# LPC55S66_cm33_core1 register map
Vendor: nxp.com; File version: 1.0
CPU: CM33 r2p0, little endian, no MPU, no FPU, VTOR, 3 interrupt priority bits
Registers are 32-bit, read-write, reset 0x0 unless marked. A register's access mark holds for its fields unless they carry their own. Offsets are from the block's base; [hi:lo] are bit positions; lines under a group give offsets from that group; {n}, {i} and the like mark numbered series; 'fields as' and 'values as' point back to an identical list.

## SCT0 — SCTimer/PWM (SCT)
Base 0x40085000
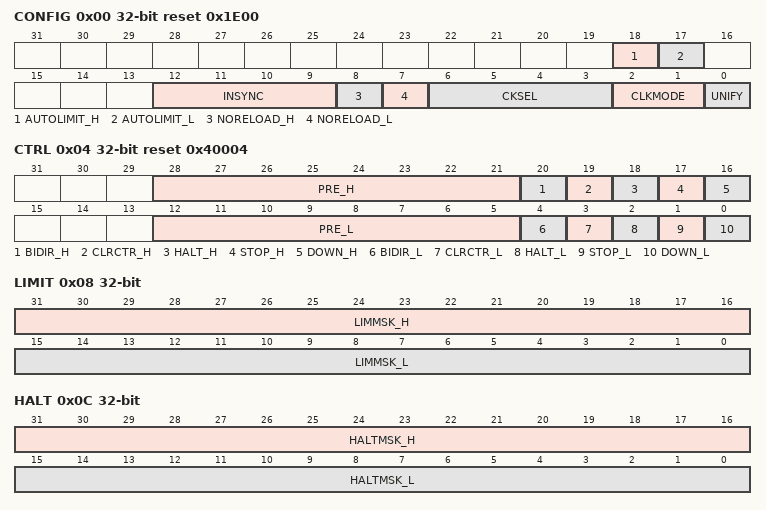
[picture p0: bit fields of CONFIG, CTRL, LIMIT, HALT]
0x00 CONFIG reset 0x1E00 — SCT configuration register
  [18] AUTOLIMIT_H — A one in this bit will cause a match on match register 0 to be treated as a de-facto LIMIT condition without the need to define an associated event. As with any LIMIT event, this automatic limit causes the counter to be cleared to zero in unidirectional mode or to change the direction of count in bi-directional mode. Software can write to set or clear this bit at any time. This bit is not used when the UNIFY bit is set.
  [17] AUTOLIMIT_L — A one in this bit causes a match on match register 0 to be treated as a de-facto LIMIT condition without the need to define an associated event. As with any LIMIT event, this automatic limit causes the counter to be cleared to zero in unidirectional mode or to change the direction of count in bi-directional mode. Software can write to set or clear this bit at any time. This bit applies to both the higher and lower registers when the UNIFY bit is set.
  [12:9] INSYNC — Synchronization for input N (bit 9 = input 0, bit 10 = input 1,, bit 12 = input 3); all other bits are reserved. A 1 in one of these bits subjects the corresponding input to synchronization to the SCT clock, before it is used to create an event. If an input is known to already be synchronous to the SCT clock, this bit may be set to 0 for faster input response. (Note: The SCT clock is the system clock for CKMODEs 0-2. It is the selected, asynchronous SCT input clock for CKMODE3). Note that the INSYNC field only affects inputs used for event generation. It does not apply to the clock input specified in the CKSEL field.
  [8] NORELOAD_H — A 1 in this bit prevents the higher match registers from being reloaded from their respective reload registers. Setting this bit eliminates the need to write to the reload registers MATCHREL if the match values are fixed. Software can write to set or clear this bit at any time. This bit is not used when the UNIFY bit is set.
  [7] NORELOAD_L — A 1 in this bit prevents the lower match registers from being reloaded from their respective reload registers. Setting this bit eliminates the need to write to the reload registers MATCHREL if the match values are fixed. Software can write to set or clear this bit at any time. This bit applies to both the higher and lower registers when the UNIFY bit is set.
  [6:3] CKSEL — SCT clock select. The specific functionality of the designated input/edge is dependent on the CLKMODE bit selection in this register.
    0=INPUT_0_RISING_EDGES (Rising edges on input 0.); 1=INPUT_0_FALLING_EDGE (Falling edges on input 0.); 2=INPUT_1_RISING_EDGES (Rising edges on input 1.); 3=INPUT_1_FALLING_EDGE (Falling edges on input 1.); 4=INPUT_2_RISING_EDGES (Rising edges on input 2.); 5=INPUT_2_FALLING_EDGE (Falling edges on input 2.); 6=INPUT_3_RISING_EDGES (Rising edges on input 3.); 7=INPUT_3_FALLING_EDGE (Falling edges on input 3.); 8=INPUT_4_RISING_EDGES (Rising edges on input 4.); 9=INPUT_4_FALLING_EDGE (Falling edges on input 4.); 10=INPUT_5_RISING_EDGES (Rising edges on input 5.); 11=INPUT_5_FALLING_EDGE (Falling edges on input 5.); 12=INPUT_6_RISING_EDGES (Rising edges on input 6.); 13=INPUT_6_FALLING_EDGE (Falling edges on input 6.); 14=INPUT_7_RISING_EDGES (Rising edges on input 7.); 15=INPUT_7_FALLING_EDGE (Falling edges on input 7.)
  [2:1] CLKMODE — SCT clock mode
    0=SYSTEM_CLOCK_MODE (System Clock Mode. The system clock clocks the entire SCT module including the counter(s) and counter prescalers.); 1=SAMPLED_SYSTEM_CLOCK_MODE (Sampled System Clock Mode. The system clock clocks the SCT module, but the counter and prescalers are only enabled to count when the designated edge is detected on the input selected by the CKSEL field. The minimum pulse width on the selected clock-gate input is 1 bus clock period. This mode is the high-performance, sampled-clock mode.); 2=SCT_INPUT_CLOCK_MODE (SCT Input Clock Mode. The input/edge selected by the CKSEL field clocks the SCT module, including the counters and prescalers, after first being synchronized to the system clock. The minimum pulse width on the clock input is 1 bus clock period. This mode is the low-power, sampled-clock mode.); 3=ASYNCHRONOUS_MODE (Asynchronous Mode. The entire SCT module is clocked directly by the input/edge selected by the CKSEL field. In this mode, the SCT outputs are switched synchronously to the SCT input clock - not the system clock. The input clock rate must be at least half the system clock rate and can be the same or faster than the system clock.)
  [0] UNIFY — SCT operation
    0=DUAL_COUNTER (The SCT operates as two 16-bit counters named COUNTER_L and COUNTER_H.); 1=UNIFIED_COUNTER (The SCT operates as a unified 32-bit counter.)
0x04 CTRL reset 0x40004 — SCT control register
  [28:21] PRE_H — Specifies the factor by which the SCT clock is prescaled to produce the H counter clock. The counter clock is clocked at the rate of the SCT clock divided by PRELH+1. Clear the counter (by writing a 1 to the CLRCTR bit) whenever changing the PRE value.
  [20] BIDIR_H — Direction select
    0=UP (The H counter counts up to its limit condition, then is cleared to zero.); 1=UP_DOWN (The H counter counts up to its limit, then counts down to a limit condition or to 0.)
  [19] CLRCTR_H — Writing a 1 to this bit clears the H counter. This bit always reads as 0.
  [18] HALT_H — When this bit is 1, the H counter does not run and no events can occur. A reset sets this bit. When the HALT_H bit is one, the STOP_H bit is cleared. It is possible to remove the halt condition while keeping the SCT in the stop condition (not running) with a single write to this register to simultaneously clear the HALT bit and set the STOP bit. Once set, this bit can only be cleared by software to restore counter operation. This bit is set on reset.
  [17] STOP_H — When this bit is 1 and HALT is 0, the H counter does not, run but I/O events related to the counter can occur. If such an event matches the mask in the Start register, this bit is cleared and counting resumes.
  [16] DOWN_H — This bit is 1 when the H counter is counting down. Hardware sets this bit when the counter is counting, a counter limit condition occurs, and BIDIR is 1. Hardware clears this bit when the counter is counting down and a limit condition occurs or when the counter reaches 0.
  [12:5] PRE_L — Specifies the factor by which the SCT clock is prescaled to produce the L or unified counter clock. The counter clock is clocked at the rate of the SCT clock divided by PRE_L+1. Clear the counter (by writing a 1 to the CLRCTR bit) whenever changing the PRE value.
  [4] BIDIR_L — L or unified counter direction select
    0=UP (Up. The counter counts up to a limit condition, then is cleared to zero.); 1=UP_DOWN (Up-down. The counter counts up to a limit, then counts down to a limit condition or to 0.)
  [3] CLRCTR_L — Writing a 1 to this bit clears the L or unified counter. This bit always reads as 0.
  [2] HALT_L — When this bit is 1, the L or unified counter does not run and no events can occur. A reset sets this bit. When the HALT_L bit is one, the STOP_L bit is cleared. It is possible to remove the halt condition while keeping the SCT in the stop condition (not running) with a single write to this register to simultaneously clear the HALT bit and set the STOP bit. Once set, only software can clear this bit to restore counter operation. This bit is set on reset.
  [1] STOP_L — When this bit is 1 and HALT is 0, the L or unified counter does not run, but I/O events related to the counter can occur. If a designated start event occurs, this bit is cleared and counting resumes.
  [0] DOWN_L — This bit is 1 when the L or unified counter is counting down. Hardware sets this bit when the counter is counting up, counter limit occurs, and BIDIR = 1.Hardware clears this bit when the counter is counting down and a limit condition occurs or when the counter reaches 0.
0x08 LIMIT — SCT limit event select register
  [31:16] LIMMSK_H — If bit n is one, event n is used as a counter limit for the H counter (event 0 = bit 16, event 1 = bit 17, etc.). The number of bits = number of events in this SCT.
  [15:0] LIMMSK_L — If bit n is one, event n is used as a counter limit for the L or unified counter (event 0 = bit 0, event 1 = bit 1, etc.). The number of bits = number of events in this SCT.
0x0C HALT — SCT halt event select register
  [31:16] HALTMSK_H — If bit n is one, event n sets the HALT_H bit in the CTRL register (event 0 = bit 16, event 1 = bit 17, etc.). The number of bits = number of events in this SCT.
  [15:0] HALTMSK_L — If bit n is one, event n sets the HALT_L bit in the CTRL register (event 0 = bit 0, event 1 = bit 1, etc.). The number of bits = number of events in this SCT.
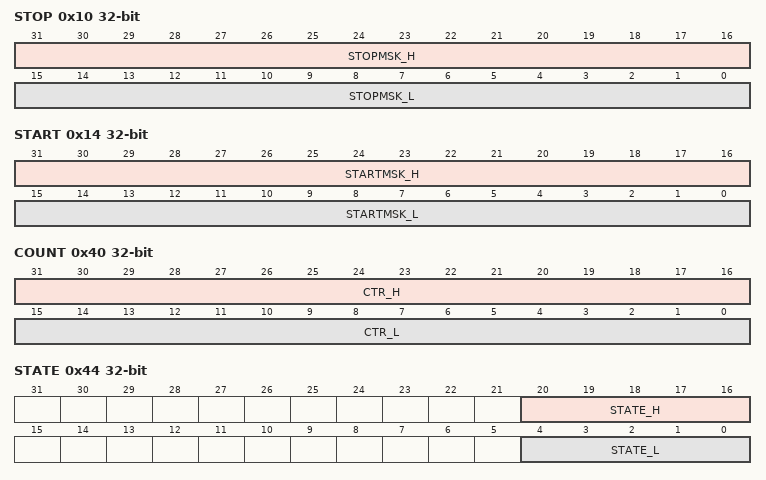
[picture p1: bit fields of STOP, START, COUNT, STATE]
0x10 STOP — SCT stop event select register
  [31:16] STOPMSK_H — If bit n is one, event n sets the STOP_H bit in the CTRL register (event 0 = bit 16, event 1 = bit 17, etc.). The number of bits = number of events in this SCT.
  [15:0] STOPMSK_L — If bit n is one, event n sets the STOP_L bit in the CTRL register (event 0 = bit 0, event 1 = bit 1, etc.). The number of bits = number of events in this SCT.
0x14 START — SCT start event select register
  [31:16] STARTMSK_H — If bit n is one, event n clears the STOP_H bit in the CTRL register (event 0 = bit 16, event 1 = bit 17, etc.). The number of bits = number of events in this SCT.
  [15:0] STARTMSK_L — If bit n is one, event n clears the STOP_L bit in the CTRL register (event 0 = bit 0, event 1 = bit 1, etc.). The number of bits = number of events in this SCT.
0x40 COUNT — SCT counter register
  [31:16] CTR_H — When UNIFY = 0, read or write the 16-bit H counter value. When UNIFY = 1, read or write the upper 16 bits of the 32-bit unified counter.
  [15:0] CTR_L — When UNIFY = 0, read or write the 16-bit L counter value. When UNIFY = 1, read or write the lower 16 bits of the 32-bit unified counter.
0x44 STATE — SCT state register
  [20:16] STATE_H — State variable.
  [4:0] STATE_L — State variable.
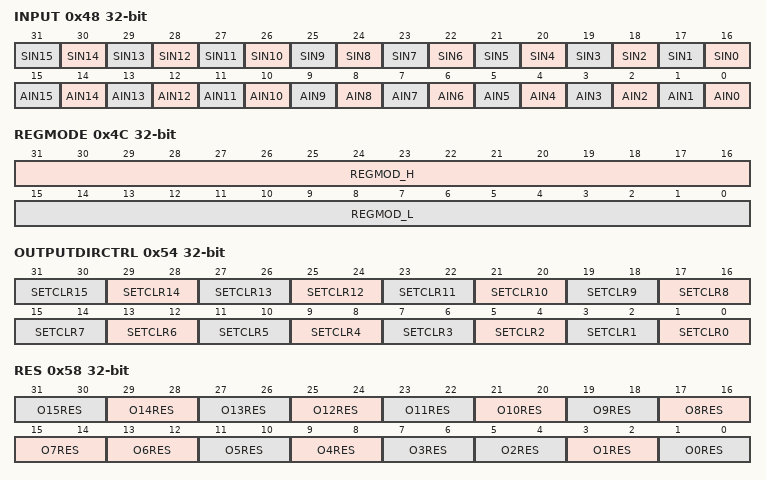
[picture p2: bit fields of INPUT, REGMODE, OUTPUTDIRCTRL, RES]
0x48 INPUT ro — SCT input register
  [n+16] SIN{n} (n=0..15) — Input {n} state. Input {n} state following the synchronization specified by INSYNC.
  [n] AIN{n} (n=0..15) — Input {n} state. Input {n} state on the last SCT clock edge.
0x4C REGMODE — SCT match/capture mode register
  [31:16] REGMOD_H — Each bit controls one match/capture register (register 0 = bit 16, register 1 = bit 17, etc.). The number of bits = number of match/captures in this SCT. 0 = register operates as match registers. 1 = register operates as capture registers.
  [15:0] REGMOD_L — Each bit controls one match/capture register (register 0 = bit 0, register 1 = bit 1, etc.). The number of bits = number of match/captures in this SCT. 0 = register operates as match register. 1 = register operates as capture register.
0x50 OUTPUT — SCT output register
  [15:0] OUT — Writing a 1 to bit n forces the corresponding output HIGH. Writing a 0 forces the corresponding output LOW (output 0 = bit 0, output 1 = bit 1, etc.). The number of bits = number of outputs in this SCT.
0x54 OUTPUTDIRCTRL — SCT output counter direction control register
  [all] fields
    0=INDEPENDENT (Set and clear do not depend on the direction of any counter.); 1=L_REVERSED (Set and clear are reversed when counter L or the unified counter is counting down.); 2=H_REVERSED (Set and clear are reversed when counter H is counting down. Do not use if UNIFY = 1.)
  [2n+1:2n] SETCLR{n} (n=0..15) — Set/clear operation on output {n}. Value 0x3 is reserved. Do not program this value.
0x58 RES — SCT conflict resolution register
  [2n+1:2n] O{n}RES (n=8..15) — Effect of simultaneous set and clear on output {n}.
    0=NO_CHANGE; 1=SET (Set output (or clear based on the SETCLR{n} field in the OUTPUTDIRCTRL register).); 2=CLEAR (Clear output (or set based on the SETCLR{n} field).); 3=TOGGLE_OUTPUT
  [15:14] O7RES — Effect of simultaneous set and clear on output 7.
    0=NO_CHANGE; 1=SET (Set output (or clear based on the SETCLR7 field in the OUTPUTDIRCTRL register).); 2=CLEAR (Clear output n (or set based on the SETCLR7 field).); 3=TOGGLE_OUTPUT
  [2n+1:2n] O{n}RES (n=3..6) — Effect of simultaneous set and clear on output {n}.
    values as O8RES
  [5:4] O2RES — Effect of simultaneous set and clear on output 2.
    0=NO_CHANGE; 1=SET (Set output (or clear based on the SETCLR2 field in the OUTPUTDIRCTRL register).); 2=CLEAR (Clear output n (or set based on the SETCLR2 field).); 3=TOGGLE_OUTPUT
  [3:2] O1RES — Effect of simultaneous set and clear on output 1.
    0=NO_CHANGE; 1=SET (Set output (or clear based on the SETCLR1 field in the OUTPUTDIRCTRL register).); 2=CLEAR (Clear output (or set based on the SETCLR1 field).); 3=TOGGLE_OUTPUT
  [1:0] O0RES — Effect of simultaneous set and clear on output 0.
    0=NO_CHANGE; 1=SET (Set output (or clear based on the SETCLR0 field in the OUTPUTDIRCTRL register).); 2=CLEAR (Clear output (or set based on the SETCLR0 field).); 3=TOGGLE_OUTPUT
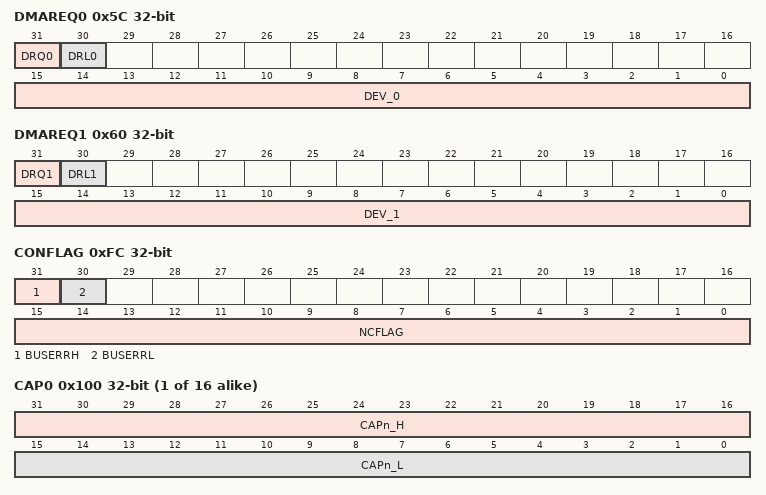
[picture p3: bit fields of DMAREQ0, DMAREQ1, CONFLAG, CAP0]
0x5C DMAREQ0 — SCT DMA request 0 register
  [31] DRQ0 — This read-only bit indicates the state of DMA Request 0. Note that if the related DMA channel is enabled and properly set up, it is unlikely that software will see this flag, it will be cleared rapidly by the DMA service. The flag remaining set could point to an issue with DMA setup.
  [30] DRL0 — A 1 in this bit triggers DMA request 0 when it loads the MATCH_L/Unified registers from the RELOAD_L/Unified registers.
  [15:0] DEV_0 — If bit n is one, event n triggers DMA request 0 (event 0 = bit 0, event 1 = bit 1, etc.). The number of bits = number of events in this SCT.
0x60 DMAREQ1 — SCT DMA request 1 register
  [31] DRQ1 — This read-only bit indicates the state of DMA Request 1. Note that if the related DMA channel is enabled and properly set up, it is unlikely that software will see this flag, it will be cleared rapidly by the DMA service. The flag remaining set could point to an issue with DMA setup.
  [30] DRL1 — A 1 in this bit triggers DMA request 1 when it loads the Match L/Unified registers from the Reload L/Unified registers.
  [15:0] DEV_1 — If bit n is one, event n triggers DMA request 1 (event 0 = bit 0, event 1 = bit 1, etc.). The number of bits = number of events in this SCT.
0xF0 EVEN — SCT event interrupt enable register
  [15:0] IEN — The SCT requests an interrupt when bit n of this register and the event flag register are both one (event 0 = bit 0, event 1 = bit 1, etc.). The number of bits = number of events in this SCT.
0xF4 EVFLAG — SCT event flag register
  [15:0] FLAG — Bit n is one if event n has occurred since reset or a 1 was last written to this bit (event 0 = bit 0, event 1 = bit 1, etc.). The number of bits = number of events in this SCT.
0xF8 CONEN — SCT conflict interrupt enable register
  [15:0] NCEN — The SCT requests an interrupt when bit n of this register and the SCT conflict flag register are both one (output 0 = bit 0, output 1 = bit 1, etc.). The number of bits = number of outputs in this SCT.
0xFC CONFLAG — SCT conflict flag register
  [31] BUSERRH — The most recent bus error from this SCT involved writing CTR H, STATE H, MATCH H, or the Output register when the H counter was not halted.
  [30] BUSERRL — The most recent bus error from this SCT involved writing CTR L/Unified, STATE L/Unified, MATCH L/Unified, or the Output register when the L/U counter was not halted. A word write to certain L and H registers can be half successful and half unsuccessful.
  [15:0] NCFLAG — Bit n is one if a no-change conflict event occurred on output n since reset or a 1 was last written to this bit (output 0 = bit 0, output 1 = bit 1, etc.). The number of bits = number of outputs in this SCT.
{0x100+4i} CAP{i} (CAP_MATCH view) (i=0..15) — SCT capture register of capture channel
  [31:16] CAPn_H — When UNIFY = 0, read the 16-bit counter value at which this register was last captured. When UNIFY = 1, read the upper 16 bits of the 32-bit value at which this register was last captured.
  [15:0] CAPn_L — When UNIFY = 0, read the 16-bit counter value at which this register was last captured. When UNIFY = 1, read the lower 16 bits of the 32-bit value at which this register was last captured.
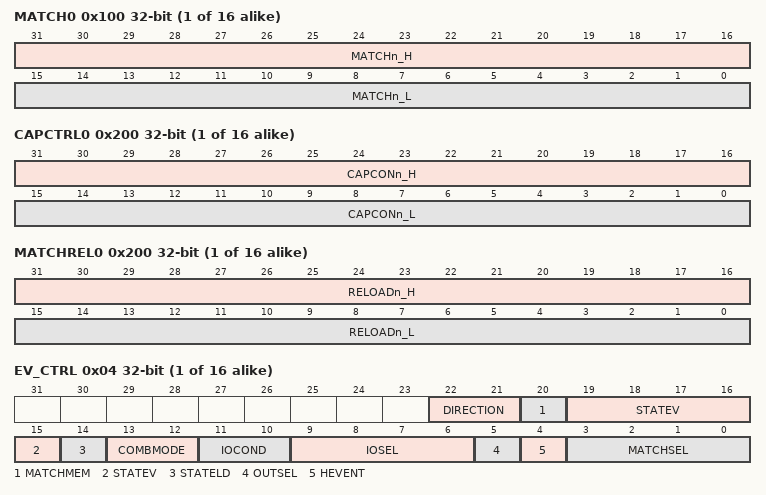
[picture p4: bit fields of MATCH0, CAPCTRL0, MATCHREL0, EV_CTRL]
{0x100+4i} MATCH{i} (CAP_MATCH view) (i=0..15) — SCT match value register of match channels
  [31:16] MATCHn_H — When UNIFY = 0, read or write the 16-bit value to be compared to the H counter. When UNIFY = 1, read or write the upper 16 bits of the 32-bit value to be compared to the unified counter.
  [15:0] MATCHn_L — When UNIFY = 0, read or write the 16-bit value to be compared to the L counter. When UNIFY = 1, read or write the lower 16 bits of the 32-bit value to be compared to the unified counter.
{0x200+4i} CAPCTRL{i} (CAPCTRL_MATCHREL view) (i=0..15) — SCT capture control register
  [31:16] CAPCONn_H — If bit m is one, event m causes the CAPn_H (UNIFY = 0) register to be loaded (event 0 = bit 16, event 1 = bit 17, etc.). The number of bits = number of match/captures in this SCT.
  [15:0] CAPCONn_L — If bit m is one, event m causes the CAPn_L (UNIFY = 0) or the CAPn (UNIFY = 1) register to be loaded (event 0 = bit 0, event 1 = bit 1, etc.). The number of bits = number of match/captures in this SCT.
{0x200+4i} MATCHREL{i} (CAPCTRL_MATCHREL view) (i=0..15) — SCT match reload value register
  [31:16] RELOADn_H — When UNIFY = 0, specifies the 16-bit to be loaded into the MATCHn_H register. When UNIFY = 1, specifies the upper 16 bits of the 32-bit value to be loaded into the MATCHn register.
  [15:0] RELOADn_L — When UNIFY = 0, specifies the 16-bit value to be loaded into the MATCHn_L register. When UNIFY = 1, specifies the lower 16 bits of the 32-bit value to be loaded into the MATCHn register.
{0x300+8i} EV[{i}] (i=0..15) group
  0x00 EV_STATE — SCT event state register 0
    [15:0] STATEMSKn — If bit m is one, event n happens in state m of the counter selected by the HEVENT bit (n = event number, m = state number; state 0 = bit 0, state 1= bit 1, etc.). The number of bits = number of states in this SCT.
  0x04 EV_CTRL — SCT event control register 0
    [22:21] DIRECTION — Direction qualifier for event generation. This field only applies when the counters are operating in BIDIR mode. If BIDIR = 0, the SCT ignores this field. Value 0x3 is reserved.
      0=DIRECTION_INDEPENDENT (Direction independent. This event is triggered regardless of the count direction.); 1=COUNTING_UP (Counting up. This event is triggered only during up-counting when BIDIR = 1.); 2=COUNTING_DOWN (Counting down. This event is triggered only during down-counting when BIDIR = 1.)
    [20] MATCHMEM — If this bit is one and the COMBMODE field specifies a match component to the triggering of this event, then a match is considered to be active whenever the counter value is GREATER THAN OR EQUAL TO the value specified in the match register when counting up, LESS THEN OR EQUAL TO the match value when counting down. If this bit is zero, a match is only be active during the cycle when the counter is equal to the match value.
    [19:15] STATEV — This value is loaded into or added to the state selected by HEVENT, depending on STATELD, when this event is the highest-numbered event occurring for that state. If STATELD and STATEV are both zero, there is no change to the STATE value.
    [14] STATELD — This bit controls how the STATEV value modifies the state selected by HEVENT when this event is the highest-numbered event occurring for that state.
      0=ADD (STATEV value is added into STATE (the carry-out is ignored).); 1=LOAD (STATEV value is loaded into STATE.)
    [13:12] COMBMODE — Selects how the specified match and I/O condition are used and combined.
      0=OR (OR. The event occurs when either the specified match or I/O condition occurs.); 1=MATCH (MATCH. Uses the specified match only.); 2=IO (IO. Uses the specified I/O condition only.); 3=AND (AND. The event occurs when the specified match and I/O condition occur simultaneously.)
    [11:10] IOCOND — Selects the I/O condition for event n. (The detection of edges on outputs lag the conditions that switch the outputs by one SCT clock). In order to guarantee proper edge/state detection, an input must have a minimum pulse width of at least one SCT clock period .
      0=LOW; 1=RISE; 2=FALL; 3=HIGH
    [9:6] IOSEL — Selects the input or output signal number associated with this event (if any). Do not select an input in this register if CKMODE is 1x. In this case the clock input is an implicit ingredient of every event.
    [5] OUTSEL — Input/output select
      0=INPUT (Selects the inputs selected by IOSEL.); 1=OUTPUT (Selects the outputs selected by IOSEL.)
    [4] HEVENT — Select L/H counter. Do not set this bit if UNIFY = 1.
      0=L_COUNTER (Selects the L state and the L match register selected by MATCHSEL.); 1=H_COUNTER (Selects the H state and the H match register selected by MATCHSEL.)
    [3:0] MATCHSEL — Selects the Match register associated with this event (if any). A match can occur only when the counter selected by the HEVENT bit is running.
{0x500+8i} OUT[{i}] (i=0..9) group
  0x00 OUT_SET — SCT output 0 set register
    [15:0] SET — A 1 in bit m selects event m to set output n (or clear it if SETCLRn = 0x1 or 0x2) output 0 = bit 0, output 1 = bit 1, etc. The number of bits = number of events in this SCT. When the counter is used in bi-directional mode, it is possible to reverse the action specified by the output set and clear registers when counting down, See the OUTPUTCTRL register.
  0x04 OUT_CLR — SCT output 0 clear register
    [15:0] CLR — A 1 in bit m selects event m to clear output n (or set it if SETCLRn = 0x1 or 0x2) event 0 = bit 0, event 1 = bit 1, etc. The number of bits = number of events in this SCT. When the counter is used in bi-directional mode, it is possible to reverse the action specified by the output set and clear registers when counting down, See the OUTPUTCTRL register.
